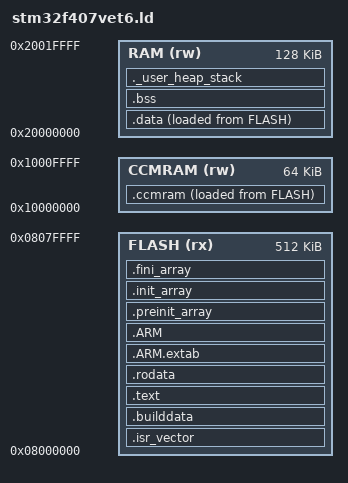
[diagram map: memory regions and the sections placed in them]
/* Entry Point */
ENTRY(Reset_Handler)

/* Highest address of the user mode stack */
_estack = 0x20020000;    /* end of RAM */
/* Generate a link error if heap and stack don't fit into RAM */
_Min_Heap_Size = 0x200;      /* required amount of heap  */
_Min_Stack_Size = 0x400; /* required amount of stack */

/* Specify the memory areas */
MEMORY
{
RAM (rw)      : ORIGIN = 0x20000000, LENGTH = 128K
CCMRAM (rw)      : ORIGIN = 0x10000000, LENGTH = 64K
FLASH (rx)      : ORIGIN = 0x8000000, LENGTH = 512K
}

PHDRS
{
    flash_text  PT_LOAD FLAGS(5);   /* R-X  = 4+1 */
    flash_data  PT_LOAD FLAGS(6);   /* RW-  = 4+2 */
    ram_data    PT_NULL FLAGS(6);   /* RW-  = 4+2 */
}

/* Define output sections */
SECTIONS
{
  /* The startup code goes first into FLASH */
  .isr_vector :
  {
    . = ALIGN(4);
    KEEP(*(.isr_vector)) /* Startup code */
    . = ALIGN(4);
  } >FLASH :flash_text

  .builddata :
  {
    . = ALIGN(4);
    _builddata_start = .;
    *(.builddata)
    . = ALIGN(4);
  } >FLASH :flash_text

  /* The program code and other data goes into FLASH */
  .text :
  {
    . = ALIGN(4);
    *(.text)           /* .text sections (code) */
    *(.text*)          /* .text* sections (code) */
    *(.glue_7)         /* glue arm to thumb code */
    *(.glue_7t)        /* glue thumb to arm code */
    *(.eh_frame)

    KEEP (*(.init))
    KEEP (*(.fini))

    . = ALIGN(4);
    _etext = .;        /* define a global symbols at end of code */
  } >FLASH :flash_text

  /* Constant data goes into FLASH */
  .rodata :
  {
    . = ALIGN(4);
    *(.rodata)         /* .rodata sections (constants, strings, etc.) */
    *(.rodata*)        /* .rodata* sections (constants, strings, etc.) */
    . = ALIGN(4);
  } >FLASH :flash_text

  .ARM.extab   : { *(.ARM.extab* .gnu.linkonce.armextab.*) } >FLASH
  .ARM : {
    __exidx_start = .;
    *(.ARM.exidx*)
    __exidx_end = .;
  } >FLASH :flash_text

  .preinit_array     :
  {
    PROVIDE_HIDDEN (__preinit_array_start = .);
    KEEP (*(.preinit_array*))
    PROVIDE_HIDDEN (__preinit_array_end = .);
  } >FLASH :flash_text
  .init_array :
  {
    PROVIDE_HIDDEN (__init_array_start = .);
    KEEP (*(SORT(.init_array.*)))
    KEEP (*(.init_array*))
    PROVIDE_HIDDEN (__init_array_end = .);
  } >FLASH :flash_text
  .fini_array :
  {
    PROVIDE_HIDDEN (__fini_array_start = .);
    KEEP (*(SORT(.fini_array.*)))
    KEEP (*(.fini_array*))
    PROVIDE_HIDDEN (__fini_array_end = .);
  } >FLASH :flash_text

  /* used by the startup to initialize data */
  _sidata = LOADADDR(.data);

  /* Initialized data sections goes into RAM, load LMA copy after code */
  .data : 
  {
    . = ALIGN(4);
    _sdata = .;        /* create a global symbol at data start */
    *(.data)           /* .data sections */
    *(.data*)          /* .data* sections */

    . = ALIGN(4);
    _edata = .;        /* define a global symbol at data end */
  } >RAM AT> FLASH :flash_data

  _siccmram = LOADADDR(.ccmram);

  /* CCM-RAM section 
  * 
  * IMPORTANT NOTE! 
  * If initialized variables will be placed in this section,
  * the startup code needs to be modified to copy the init-values.  
  */
  .ccmram :
  {
    . = ALIGN(4);
    _sccmram = .;       /* create a global symbol at ccmram start */
    *(.ccmram)
    *(.ccmram*)

    . = ALIGN(4);
    _eccmram = .;       /* create a global symbol at ccmram end */
  } >CCMRAM AT> FLASH :flash_data


  /* Uninitialized data section */
  . = ALIGN(4);
  .bss :
  {
    /* This is used by the startup in order to initialize the .bss secion */
    _sbss = .;         /* define a global symbol at bss start */
    __bss_start__ = _sbss;
    *(.bss)
    *(.bss*)
    *(COMMON)

    . = ALIGN(4);
    _ebss = .;         /* define a global symbol at bss end */
    __bss_end__ = _ebss;
  } >RAM : ram_data

  /* User_heap_stack section, used to check that there is enough RAM left */
  ._user_heap_stack :
  {
    . = ALIGN(8);
    PROVIDE ( end = . );
    PROVIDE ( _end = . );
    . = . + _Min_Heap_Size;
    . = . + _Min_Stack_Size;
    . = ALIGN(8);
  } >RAM :ram_data



  /* Remove information from the standard libraries */
  /DISCARD/ :
  {
    libc.a ( * )
    libm.a ( * )
    libgcc.a ( * )
  }

  .ARM.attributes 0 : { *(.ARM.attributes) }
}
